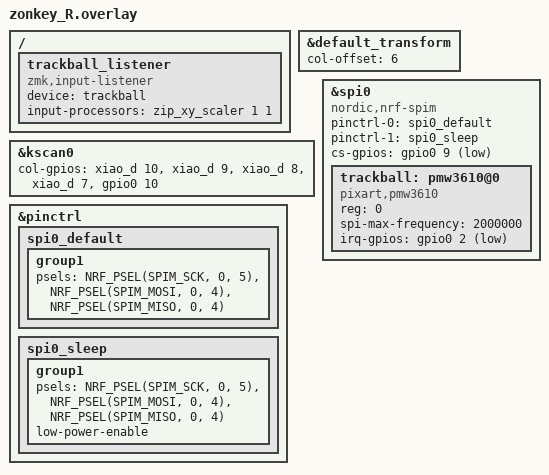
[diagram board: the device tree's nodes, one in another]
#include "zonkey.dtsi"
#include <dt-bindings/zmk/input_transform.h>

/ {
    /* trackball_listener の定義 (Zephyr 4.1 / Studioモジュール対応版) */
    trackball_listener: trackball_listener {
        compatible = "zmk,input-listener";
        status = "okay";
        device = <&trackball>;
        input-processors = <&zip_xy_scaler 1 1>; // Studio側で倍率変更できるようにプロセッサを噛ませる
    };
};

&default_transform {
    col-offset = <6>;
};

&kscan0 {
    col-gpios
        = <&xiao_d 10 GPIO_ACTIVE_HIGH>
        , <&xiao_d 9 GPIO_ACTIVE_HIGH> 
        , <&xiao_d 8 GPIO_ACTIVE_HIGH> 
        , <&xiao_d 7 GPIO_ACTIVE_HIGH> 
        , <&gpio0 10 GPIO_ACTIVE_HIGH>
        ;
};

&pinctrl {
    spi0_default: spi0_default {
        group1 {
            psels = <NRF_PSEL(SPIM_SCK, 0, 5)>,
                <NRF_PSEL(SPIM_MOSI, 0, 4)>,
                <NRF_PSEL(SPIM_MISO, 0, 4)>;
        };
    };

    spi0_sleep: spi0_sleep {
        group1 {
            psels = <NRF_PSEL(SPIM_SCK, 0, 5)>,
                <NRF_PSEL(SPIM_MOSI, 0, 4)>,
                <NRF_PSEL(SPIM_MISO, 0, 4)>;
            low-power-enable;
        };
    };
};

&spi0 {
    status = "okay";
    compatible = "nordic,nrf-spim";
    pinctrl-0 = <&spi0_default>;
    pinctrl-1 = <&spi0_sleep>;
    pinctrl-names = "default", "sleep";
    cs-gpios = <&gpio0 9 GPIO_ACTIVE_LOW>;

    trackball: pmw3610@0 { // ← 内蔵ドライバーが要求するノード名形式
        status = "okay";
        compatible = "pixart,pmw3610";
        reg = <0>;
        spi-max-frequency = <2000000>;
        irq-gpios = <&gpio0 2 (GPIO_ACTIVE_LOW | GPIO_PULL_UP)>;
        /* Zephyr 4.1環境かつStudioモジュールを使う場合、
           automouseやscrollのレイヤー指定はここへの直書きではなく、
           Studio（画面側）や、cormoran氏のインプットプロセッサ側でリアルタイム制御します。
        */
    };
};
